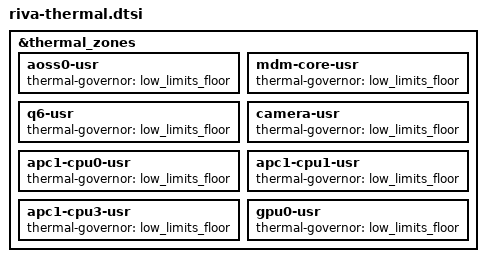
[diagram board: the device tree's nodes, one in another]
&thermal_zones {
	aoss0-usr {
		thermal-governor = "low_limits_floor";
	};

	mdm-core-usr {
		thermal-governor = "low_limits_floor";
	};

	q6-usr {
		thermal-governor = "low_limits_floor";
	};

	camera-usr {
		thermal-governor = "low_limits_floor";
	};
	
	apc1-cpu0-usr {
		thermal-governor = "low_limits_floor";
	};

	apc1-cpu1-usr {
		thermal-governor = "low_limits_floor";
	};

	apc1-cpu3-usr {
		thermal-governor = "low_limits_floor";
 	};

	gpu0-usr {
		thermal-governor = "low_limits_floor";
	};
};
